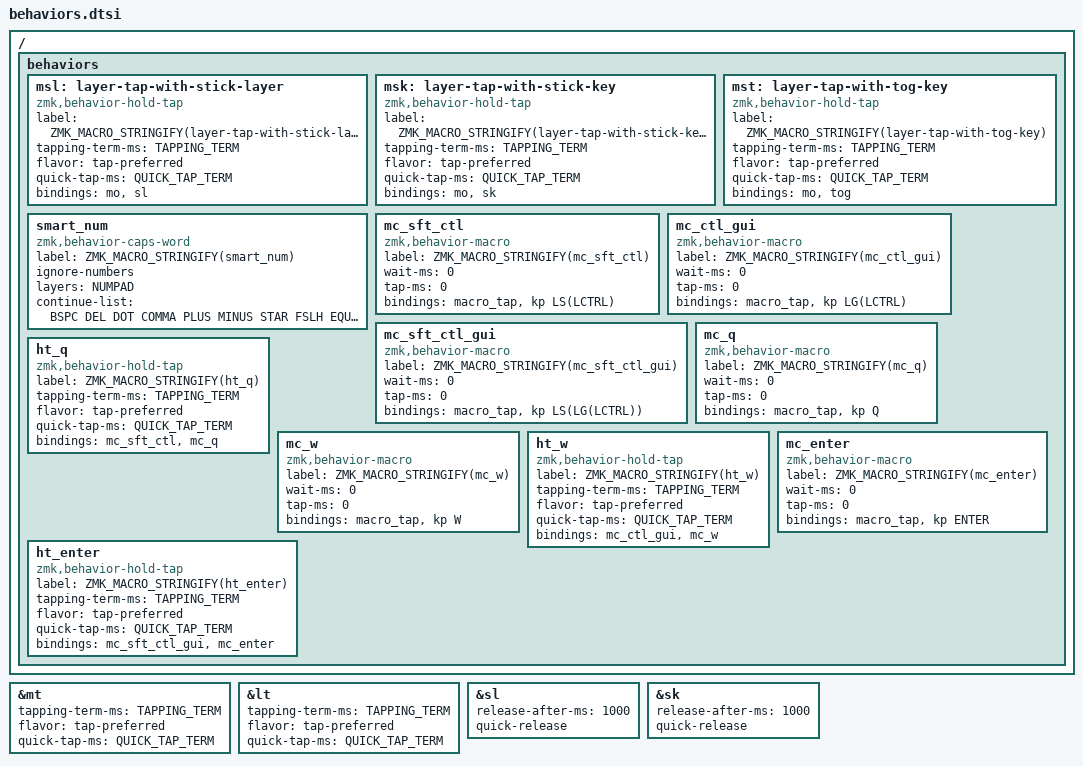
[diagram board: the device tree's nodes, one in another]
/*
*
* Copyright (c) 2022 Rafael Romão
* SPDX-License-Identifier: MIT
*
*/

&mt {
    tapping-term-ms = <TAPPING_TERM>;
    flavor = "tap-preferred";
    quick-tap-ms = <QUICK_TAP_TERM>;
};

&lt {
    tapping-term-ms = <TAPPING_TERM>;
    flavor = "tap-preferred";
    quick-tap-ms = <QUICK_TAP_TERM>;
};

&sl {
    release-after-ms = <1000>;
    quick-release;
};

&sk {
    release-after-ms = <1000>;
    quick-release;
};

/ {
    behaviors {
        msl: layer-tap-with-stick-layer {
            compatible = "zmk,behavior-hold-tap";
            label = ZMK_MACRO_STRINGIFY(layer-tap-with-stick-layer);
            #binding-cells = <2>;
            tapping-term-ms = <TAPPING_TERM>;
            flavor = "tap-preferred";
            quick-tap-ms = <QUICK_TAP_TERM>;
            bindings = <&mo>, <&sl>;
        };
        msk: layer-tap-with-stick-key {
            compatible = "zmk,behavior-hold-tap";
            label = ZMK_MACRO_STRINGIFY(layer-tap-with-stick-key);
            #binding-cells = <2>;
            tapping-term-ms = <TAPPING_TERM>;
            flavor = "tap-preferred";
            quick-tap-ms = <QUICK_TAP_TERM>;
            bindings = <&mo>, <&sk>;
        };
        mst: layer-tap-with-tog-key {
            compatible = "zmk,behavior-hold-tap";
            label = ZMK_MACRO_STRINGIFY(layer-tap-with-tog-key);
            #binding-cells = <2>;
            tapping-term-ms = <TAPPING_TERM>;
            flavor = "tap-preferred";
            quick-tap-ms = <QUICK_TAP_TERM>;
            bindings = <&mo>, <&tog>;
        };

        smart_num: smart_num {
            compatible = "zmk,behavior-caps-word";
            label = ZMK_MACRO_STRINGIFY(smart_num);
            ignore-numbers;
			#binding-cells = <0>;
            layers = <NUMPAD>;
            continue-list = <BSPC DEL DOT COMMA PLUS MINUS STAR FSLH EQUAL F1 F2 F3 F4 F5 F6 F7 F8 F9 F10 F11 F12>;
        };

        mc_sft_ctl: mc_sft_ctl { 
            compatible = "zmk,behavior-macro"; 
            label = ZMK_MACRO_STRINGIFY(mc_sft_ctl);
            #binding-cells = <0>;
            wait-ms = <0>;
            tap-ms = <0>;
            bindings = <&macro_tap &kp LS(LCTRL)>;
        };

        mc_ctl_gui: mc_ctl_gui { 
            compatible = "zmk,behavior-macro"; 
            label = ZMK_MACRO_STRINGIFY(mc_ctl_gui);
            #binding-cells = <0>;
            wait-ms = <0>;
            tap-ms = <0>;
            bindings = <&macro_tap &kp LG(LCTRL)>;
        };

        mc_sft_ctl_gui: mc_sft_ctl_gui { 
            compatible = "zmk,behavior-macro"; 
            label = ZMK_MACRO_STRINGIFY(mc_sft_ctl_gui);
            #binding-cells = <0>;
            wait-ms = <0>;
            tap-ms = <0>;
            bindings = <&macro_tap &kp LS(LG(LCTRL))>;
        };

        mc_q: mc_q { 
            compatible = "zmk,behavior-macro"; 
            label = ZMK_MACRO_STRINGIFY(mc_q);
            #binding-cells = <0>;
            wait-ms = <0>;
            tap-ms = <0>;
            bindings = <&macro_tap &kp Q>;
        };

        ht_q: ht_q {
            compatible = "zmk,behavior-hold-tap";
            label = ZMK_MACRO_STRINGIFY(ht_q);
            #binding-cells = <2>;
            tapping-term-ms = <TAPPING_TERM>;
            flavor = "tap-preferred";
            quick-tap-ms = <QUICK_TAP_TERM>;
            bindings = <&mc_sft_ctl>, <&mc_q>;
        };

        mc_w: mc_w { 
            compatible = "zmk,behavior-macro"; 
            label = ZMK_MACRO_STRINGIFY(mc_w);
            #binding-cells = <0>;
            wait-ms = <0>;
            tap-ms = <0>;
            bindings = <&macro_tap &kp W>;
        };

        ht_w: ht_w {
            compatible = "zmk,behavior-hold-tap";
            label = ZMK_MACRO_STRINGIFY(ht_w);
            #binding-cells = <2>;
            tapping-term-ms = <TAPPING_TERM>;
            flavor = "tap-preferred";
            quick-tap-ms = <QUICK_TAP_TERM>;
            bindings = <&mc_ctl_gui>, <&mc_w>;
        };

        mc_enter: mc_enter { 
            compatible = "zmk,behavior-macro"; 
            label = ZMK_MACRO_STRINGIFY(mc_enter);
            #binding-cells = <0>;
            wait-ms = <0>;
            tap-ms = <0>;
            bindings = <&macro_tap &kp ENTER>;
        };

        ht_enter: ht_enter {
            compatible = "zmk,behavior-hold-tap";
            label = ZMK_MACRO_STRINGIFY(ht_enter);
            #binding-cells = <2>;
            tapping-term-ms = <TAPPING_TERM>;
            flavor = "tap-preferred";
            quick-tap-ms = <QUICK_TAP_TERM>;
            bindings = <&mc_sft_ctl_gui>, <&mc_enter>;
        };

    };
};
